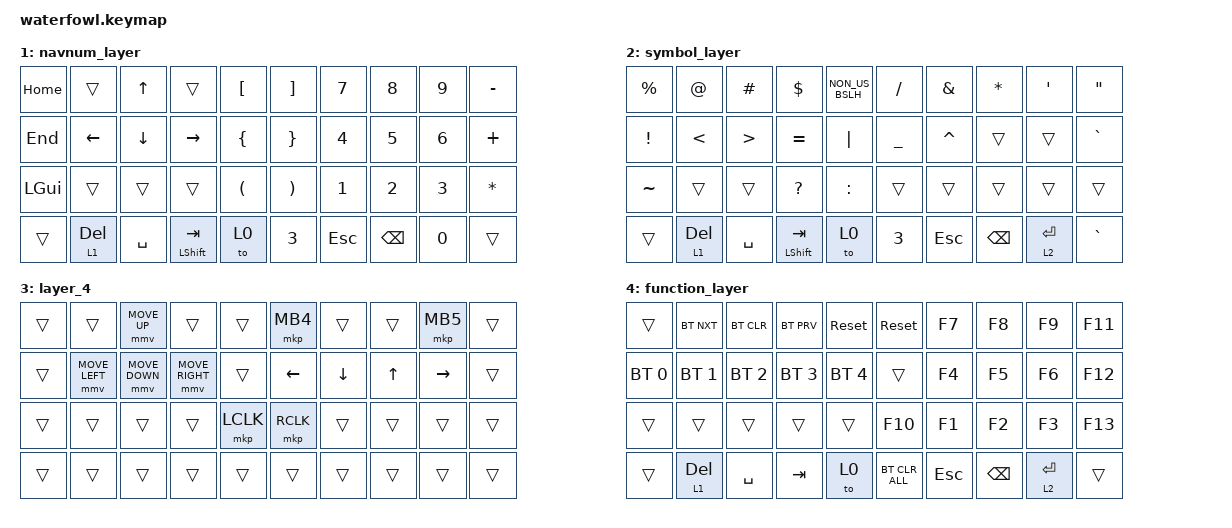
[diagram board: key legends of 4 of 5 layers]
/*
 * Copyright (c) 2022 The ZMK Contributors
 *
 * SPDX-License-Identifier: MIT
 */

#include <dt-bindings/zmk/mouse.h>
#include <behaviors.dtsi>
#include <dt-bindings/zmk/bt.h>
#include <dt-bindings/zmk/keys.h>
#include <dt-bindings/zmk/pointing.h>

/ {
    keymap {
        compatible = "zmk,keymap";

        default_layer {
            /* QWERTY
 *
 * ,----------------------------------.                      ,----------------------------------.
 * |   Q  |   W  |   E  |   R  |   T  |                      |   Y  |   U  |   I  |   O  |   P  |
 * |------+------+------+------+------|                      |------+------+------+------+------|
 * |   A  |   S  |   D  |   F  |   G  |                      |   H  |   J  |   K  |   L  |   ;  |
 * |------+------+------+------+------|  ,-----.    ,-----.  |------+------+------+------+------|
 * |   Z  |   X  |   C  |   V  |   B  |  |  2  |    |  3  |  |   N  |   M  |   ,  |   .  |   /  |
 * `----------------------------------'  `-----'    `-----'  `----------------------------------'
 *          ,-----.   ,--------------------.            ,--------------------.   ,-----.
 *          |  1  |   | DEL | SPACE | TAB  |            |  ESC  | BS | ENTER |   |  4  |
 *          `-----'   `--------------------'            `--------------------'   `-----'
 */

            bindings = <
&kp Q   &kp W      &kp E      &kp R           &kp T        &kp Y       &kp U    &kp I      &kp O      &kp P
&kp A   &kp S      &kp D      &kp F           &kp G        &kp H       &kp J    &kp K      &kp L      &mt RCTRL SEMI
&kp Z   &kp X      &kp C      &kp V           &kp B        &kp N       &kp M    &kp COMMA  &kp DOT    &mt LALT FSLH
&tog 3  &lt 1 DEL  &kp SPACE  &mt LSHIFT TAB  &kp LC(N0)   &kp RC (W)  &kp ESC  &kp BSPC   &lt 2 RET  &tog 4
            >;

            sensor-bindings =
                <&inc_dec_kp DOWN UP>,
                <&inc_dec_kp LC(EQUAL) LC(MINUS)>,
                <&inc_dec_kp PAGE_DOWN PAGE_UP>,
                <&inc_dec_kp LEFT RIGHT>;
        };

        navnum_layer {
            /* NAVNUM
 *
 * ,----------------------------------.                      ,----------------------------------.
 * |      | PgUp |  UP  | PgDn |      |                      |   /  |   7  |   8  |   9  |   -  |
 * |------+------+------+------+------|                      |------+------+------+------+------|
 * | Home | Left | Down | Right| End  |                      |   =  |   4  |   5  |   6  |   +  |
 * |------+------+------+------+------|  ,-----.    ,-----.  |------+------+------+------+------|
 * |      |      |  INS |      |      |  |  2  |    |  3  |  |   0  |   1  |   2  |   3  |   *  |
 * `----------------------------------'  `-----'    `-----'  `----------------------------------'
 *          ,-----.   ,--------------------.            ,--------------------.   ,-----.
 *          |  1  |   | DEL | SPACE | MO(3)|            |  ESC  | BS | ENTER |   |  4  |
 *          `-----'   `--------------------'            `--------------------'   `-----'
 */

            bindings = <
&kp HOME      &trans     &kp UP     &trans          &kp LBKT    &kp RBKT  &kp N7   &kp N8    &kp N9  &kp MINUS
&kp END       &kp LEFT   &kp DOWN   &kp RIGHT       &kp LBRC    &kp RBRC  &kp N4   &kp N5    &kp N6  &kp PLUS
&kp LEFT_GUI  &trans     &trans     &trans          &kp LPAR    &kp RPAR  &kp N1   &kp N2    &kp N3  &kp ASTERISK
&trans        &lt 1 DEL  &kp SPACE  &mt LSHIFT TAB  &to 0       &kp N3    &kp ESC  &kp BSPC  &kp N0  &trans
            >;

            sensor-bindings =
                <&inc_dec_kp DOWN UP>,
                <&inc_dec_kp LC(EQUAL) LC(MINUS)>,
                <&inc_dec_kp PAGE_DOWN PAGE_UP>,
                <&inc_dec_kp LEFT RIGHT>;
        };

        symbol_layer {
            /* SYM
 *
 * ,----------------------------------.                      ,----------------------------------.
 * |   %  |   @  |   [  |   ]  |   \  |                      |      |      |   ^  |      |      |
 * |------+------+------+------+------|                      |------+------+------+------+------|
 * |   #  |   !  |   (  |   )  |   |  |                      |   _  |   '  |   "  |   ~  |   `  |
 * |------+------+------+------+------|  ,-----.    ,-----.  |------+------+------+------+------|
 * |   $  |      |   {  |   }  |   &  |  |  2  |    |  3  |  |      |      |      |      |      |
 * `----------------------------------'  `-----'    `-----'  `----------------------------------'
 *          ,-----.   ,--------------------.            ,--------------------.   ,-----.
 *          |  1  |   | DEL | SPACE | TAB  |            |  ESC  | BS | ENTER |   |  4  |
 *          `-----'   `--------------------'            `--------------------'   `-----'
 */

            bindings = <
&kp PRCNT  &kp AT     &kp HASH   &kp DLLR        &kp NON_US_BSLH    &kp FSLH   &kp AMPERSAND  &kp ASTERISK  &kp SQT    &kp DQT
&kp EXCL   &kp LT     &kp GT     &kp EQUAL       &kp PIPE           &kp UNDER  &kp CARET      &trans        &trans     &kp GRAVE
&kp TILDE  &trans     &trans     &kp QMARK       &kp COLON          &trans     &trans         &trans        &trans     &trans
&trans     &lt 1 DEL  &kp SPACE  &mt LSHIFT TAB  &to 0              &kp N3     &kp ESC        &kp BSPC      &lt 2 RET  &kp GRAVE
            >;

            sensor-bindings =
                <&inc_dec_kp DOWN UP>,
                <&inc_dec_kp LC(EQUAL) LC(MINUS)>,
                <&inc_dec_kp PAGE_DOWN PAGE_UP>,
                <&inc_dec_kp LEFT RIGHT>;
        };

        layer_4 {
            bindings = <
&trans  &trans          &mmv MOVE_UP    &trans           &trans       &mkp MB4   &trans    &trans  &mkp MB5   &trans
&trans  &mmv MOVE_LEFT  &mmv MOVE_DOWN  &mmv MOVE_RIGHT  &trans       &kp LEFT   &kp DOWN  &kp UP  &kp RIGHT  &trans
&trans  &trans          &trans          &trans           &mkp LCLK    &mkp RCLK  &trans    &trans  &trans     &trans
&trans  &trans          &trans          &trans           &trans       &trans     &trans    &trans  &trans     &trans
            >;

            sensor-bindings =
                <&inc_dec_kp DOWN UP>,
                <&inc_dec_kp LC(EQUAL) LC(MINUS)>,
                <&inc_dec_kp PAGE_DOWN PAGE_UP>,
                <&inc_dec_kp LEFT RIGHT>;
        };

        function_layer {
            /* FUNC
 *
 * ,----------------------------------.                      ,----------------------------------.
 * |      |      | BTCLR|      | Reset|                      | Reset|  F7  |  F8  |  F9  |  F11 |
 * |------+------+------+------+------|                      |------+------+------+------+------|
 * |  BT0 |  BT1 |  BT2 |  BT3 |  BT4 |                      |      |  F4  |  F5  |  F6  |  F12 |
 * |------+------+------+------+------|  ,-----.    ,-----.  |------+------+------+------+------|
 * |      |      |      |      |      |  |  2  |    |  3  |  |  F10 |  F1  |  F2  |  F3  |  F13 |
 * `----------------------------------'  `-----'    `-----'  `----------------------------------'
 *          ,-----.   ,--------------------.            ,--------------------.   ,-----.
 *          |  1  |   | DEL | SPACE | TAB  |            |  ESC  | BS | ENTER |   |  4  |
 *          `-----'   `--------------------'            `--------------------'   `-----'
 */

            bindings = <
&trans        &bt BT_NXT    &bt BT_CLR    &bt BT_PRV    &sys_reset      &sys_reset      &kp F7   &kp F8    &kp F9     &kp F11
&bt BT_SEL 0  &bt BT_SEL 1  &bt BT_SEL 2  &bt BT_SEL 3  &bt BT_SEL 4    &trans          &kp F4   &kp F5    &kp F6     &kp F12
&trans        &trans        &trans        &trans        &trans          &kp F10         &kp F1   &kp F2    &kp F3     &kp F13
&trans        &lt 1 DEL     &kp SPACE     &kp TAB       &to 0           &bt BT_CLR_ALL  &kp ESC  &kp BSPC  &lt 2 RET  &trans
            >;

            sensor-bindings =
                <&inc_dec_kp DOWN UP>,
                <&inc_dec_kp LC(EQUAL) LC(MINUS)>,
                <&inc_dec_kp PAGE_DOWN PAGE_UP>,
                <&inc_dec_kp LEFT RIGHT>;
        };
    };
};
